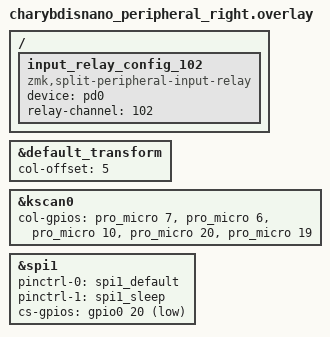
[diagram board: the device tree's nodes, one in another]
/*
 * Copyright (c) 2020 ZMK Contributors
 *
 * SPDX-License-Identifier: MIT
 */
 
#include "charybdisnano.dtsi"

&default_transform {
	col-offset = <5>;
};

&kscan0 {
	col-gpios
		= <&pro_micro 7 GPIO_ACTIVE_HIGH>
		, <&pro_micro 6 GPIO_ACTIVE_HIGH>
		, <&pro_micro 10 GPIO_ACTIVE_HIGH>
		, <&pro_micro 20 GPIO_ACTIVE_HIGH> 
		, <&pro_micro 19 GPIO_ACTIVE_HIGH>
		;
};

#include "charybdisnano_trackball.dtsi"

/* enable &pd0 on split peripheral. typical input device for zephyr input subsystem. */
/* NOTE 1: use the same device alias (&pd0) on central and peripheral(s) is alright. */
/* NOTE 2: input event shall be intecepted by module `zmk-split-peripheral-input-relay`. */
&spi1 {
  status = "okay";
	pinctrl-0 = <&spi1_default>;
	pinctrl-1 = <&spi1_sleep>;
	pinctrl-names = "default", "sleep";
	cs-gpios = <&gpio0 20 GPIO_ACTIVE_LOW>;
};

/ {
	/* for peripheral side, define (input-device)-to-(relay-channel) mapping */
	input_relay_config_102 {
		compatible = "zmk,split-peripheral-input-relay";

		/* peripheral side input device, used to be intecepted and be resurrected on central */
		device = <&pd0>;
		
		/* channel id, used to annotate raw input event */
		/* NOTE: should matching relay-channel on central overlay */
		relay-channel = <102>;
	};
};
